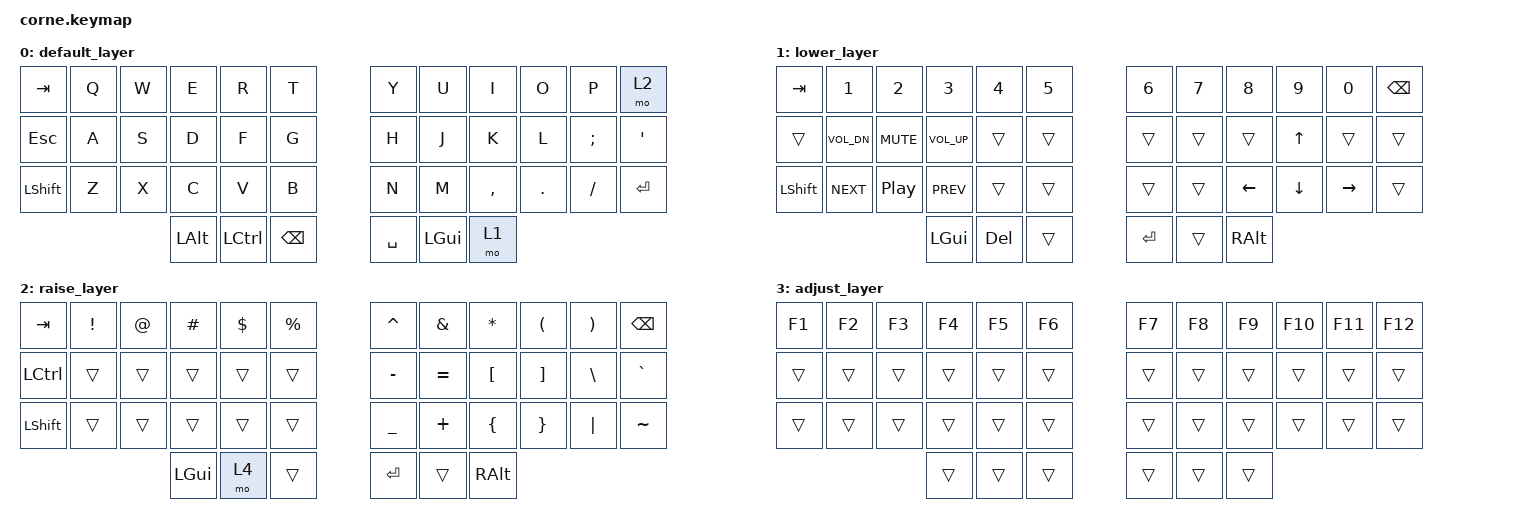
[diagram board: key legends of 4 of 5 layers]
/*
 * Copyright (c) 2020 The ZMK Contributors
 *
 * SPDX-License-Identifier: MIT
 * wanna use this nice!view repo https://github.com/M165437/nice-view-gem
 * Need to fix this keymap for so its as close my qmk keymap as possible, but also to use the new features of zmk like tap dance and bt keys.
 */

#include <behaviors.dtsi>
#include <dt-bindings/zmk/keys.h>
#include <dt-bindings/zmk/bt.h>


/ {
    behaviors {
        td_EML: tap_dance_0 {
            compatible = "zmk,behavior-tap-dance";
            #binding-cells = <0>;
            tapping-term-ms = <200>;
            bindings = <&kp ESC>, <&mo 2>;
        };
    };

// &td_EML for esc when tapped and mo 2 when held.

    keymap {
        compatible = "zmk,keymap";

        default_layer {
                        bindings = <
   &kp TAB   &kp Q &kp W &kp E &kp R &kp T   &kp Y &kp U  &kp I     &kp O   &kp P    &mo 2
   &kp ESC    &kp A &kp S &kp D &kp F &kp G   &kp H &kp J  &kp K     &kp L   &kp SEMI &kp SQT
   &kp LSHFT &kp Z &kp X &kp C &kp V &kp B   &kp N &kp M  &kp COMMA &kp DOT &kp FSLH &kp RET
                  &kp LALT &kp LCTRL &kp BSPC   &kp SPACE &kp LGUI &mo 1
                        >;
                };
                lower_layer {
                        bindings = <
   &kp TAB    &kp N1       &kp N2      &kp N3       &kp N4    &kp N5             &kp N6   &kp N7   &kp N8    &kp N9    &kp N0 &kp BSPC
   &trans     &kp C_VOL_DN &kp C_MUTE  &kp C_VOL_UP &trans    &trans             &trans   &trans   &trans    &kp UP    &trans &trans
   &kp LSHFT  &kp C_NEXT   &kp C_PP    &kp C_PREV   &trans    &trans             &trans   &trans   &kp LEFT  &kp DOWN  &kp RIGHT &trans
                                       &kp LGUI     &kp DEL   &trans          &kp RET  &trans   &kp RALT
                        >;
                };

                raise_layer {
                        bindings = <
   &kp  TAB  &kp EXCL &kp AT &kp HASH &kp DLLR &kp PRCNT   &kp CARET &kp AMPS  &kp ASTRK &kp LPAR &kp RPAR &kp BSPC
   &kp LCTRL &trans   &trans &trans   &trans   &trans      &kp MINUS &kp EQUAL &kp LBKT  &kp RBKT &kp BSLH &kp GRAVE
   &kp LSHFT &trans   &trans &trans   &trans   &trans      &kp UNDER &kp PLUS  &kp LBRC  &kp RBRC &kp PIPE &kp TILDE
                                &kp LGUI &mo 4 &trans      &kp RET   &trans    &kp RALT
                        >;
                };
                adjust_layer {
                        bindings = <
   &kp F1 &kp F2  &kp F3 &kp F4 &kp F5 &kp F6   &kp F7 &kp F8  &kp F9 &kp F10 &kp F11 &kp F12
   &trans &trans  &trans &trans &trans &trans   &trans &trans  &trans &trans &trans &trans
   &trans &trans  &trans &trans &trans &trans   &trans &trans  &trans &trans &trans &trans
                         &trans &trans &trans   &trans &trans  &trans
                        >;
                };
                bluetooth_layer {
                        bindings = <
   &trans     &trans         &trans       &trans       &trans       &trans         &trans &trans  &trans &trans &trans &trans
   &bt BT_CLR &bt BT_SEL 0   &bt BT_SEL 1 &bt BT_SEL 2 &bt BT_SEL 3 &bt BT_SEL 4   &trans &trans  &trans &trans &trans &trans
   &trans     &trans         &trans       &trans       &trans       &trans         &trans &trans  &trans &trans &trans &trans
                             &trans       &trans       &trans       &trans         &trans &trans  &trans
                        >;
                };
        };
};
